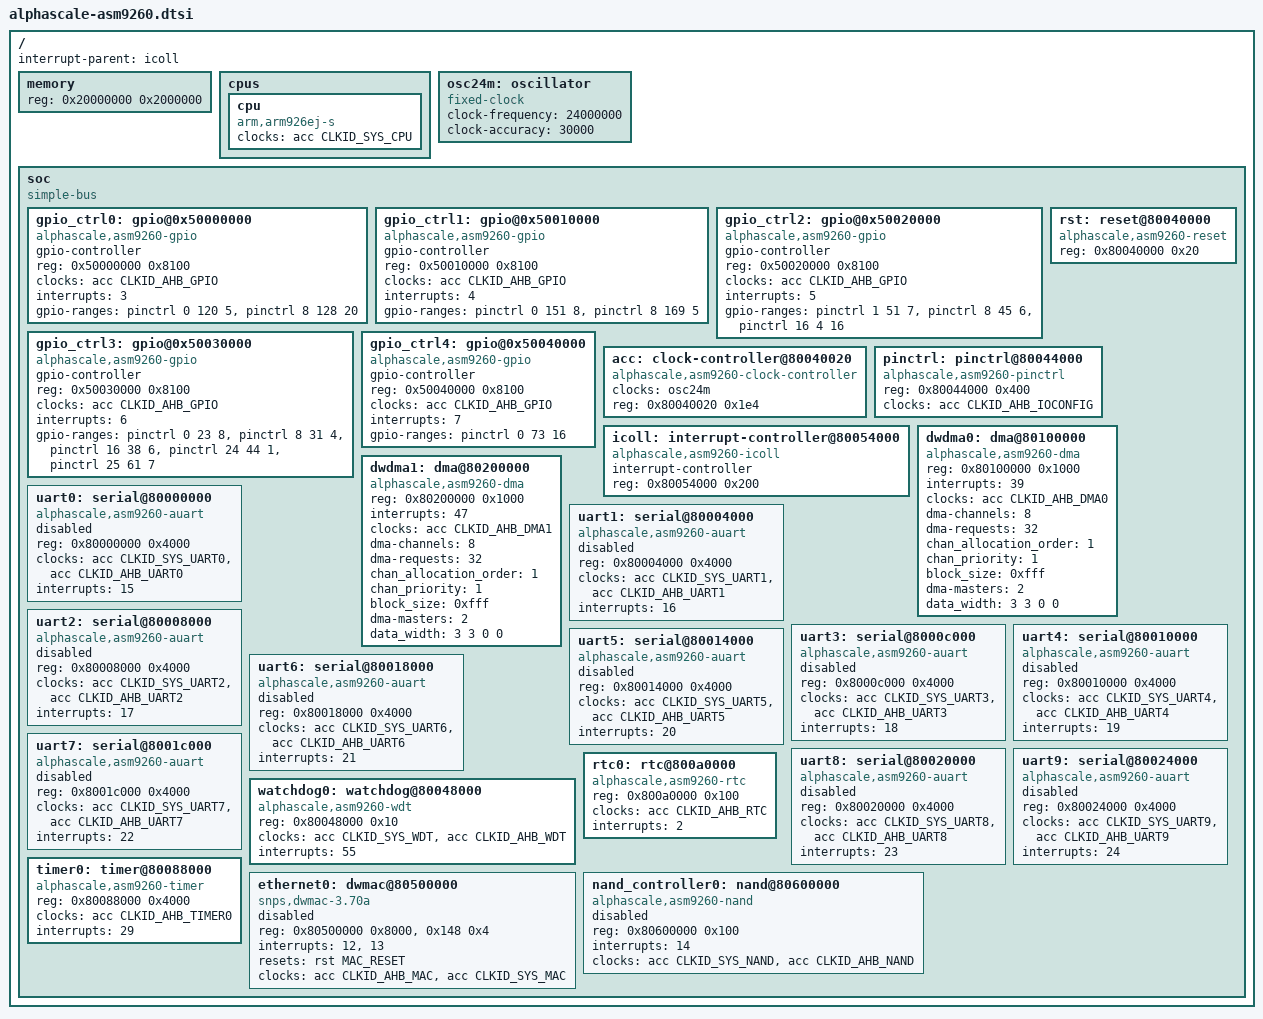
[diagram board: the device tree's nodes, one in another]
/*
 * Copyright 2014 Oleksij Rempel <linux@rempel-privat.de>
 *
 * Licensed under the X11 license or the GPL v2 (or later)
 */

#include "skeleton.dtsi"
#include <dt-bindings/clock/alphascale,asm9260.h>
#include <dt-bindings/reset/alphascale,asm9260-rst.h>

/ {
	interrupt-parent = <&icoll>;

	memory {
		device_type = "memory";
		reg = <0x20000000 0x2000000>;
	};

	cpus {
		#address-cells = <0>;
		#size-cells = <0>;

		cpu {
			compatible = "arm,arm926ej-s";
			device_type = "cpu";
			clocks = <&acc CLKID_SYS_CPU>;
		};
	};

	osc24m: oscillator {
		compatible = "fixed-clock";
		#clock-cells = <0>;
		clock-frequency = <24000000>;
		clock-accuracy = <30000>;
	};

	soc {
		#address-cells = <1>;
		#size-cells = <1>;
		compatible = "simple-bus";
		ranges;

		gpio_ctrl0: gpio@0x50000000 {
			gpio-controller;
			compatible = "alphascale,asm9260-gpio", "alphascale,asm9260-gpio-0";
			reg = <0x50000000 0x8100>;
			clocks = <&acc CLKID_AHB_GPIO>;
			clock-names = "ahb";
			interrupts = <3>;
			#gpio-cells = <2>;
			gpio-ranges = <&pinctrl 0 120 5>,
				      <&pinctrl 8 128 20>;
		};

		gpio_ctrl1: gpio@0x50010000 {
			gpio-controller;
			compatible = "alphascale,asm9260-gpio", "alphascale,asm9260-gpio-1";
			reg = <0x50010000 0x8100>;
			clocks = <&acc CLKID_AHB_GPIO>;
			clock-names = "ahb";
			interrupts = <4>;
			#gpio-cells = <2>;
			gpio-ranges = <&pinctrl 0 151 8>,
				      <&pinctrl 8 169 5>;
		};

		gpio_ctrl2: gpio@0x50020000 {
			gpio-controller;
			compatible = "alphascale,asm9260-gpio", "alphascale,asm9260-gpio-2";
			reg = <0x50020000 0x8100>;
			clocks = <&acc CLKID_AHB_GPIO>;
			clock-names = "ahb";
			interrupts = <5>;
			#gpio-cells = <2>;
			gpio-ranges = <&pinctrl 1 51 7>,
				      <&pinctrl 8 45 6>,
				      <&pinctrl 16 4 16>;
		};

		gpio_ctrl3: gpio@0x50030000 {
			gpio-controller;
			compatible = "alphascale,asm9260-gpio", "alphascale,asm9260-gpio-3";
			reg = <0x50030000 0x8100>;
			clocks = <&acc CLKID_AHB_GPIO>;
			clock-names = "ahb";
			interrupts = <6>;
			#gpio-cells = <2>;
			gpio-ranges = <&pinctrl 0 23 8>,
				      <&pinctrl 8 31 4>,
				      <&pinctrl 16 38 6>,
				      <&pinctrl 24 44 1>,
				      <&pinctrl 25 61 7>;
		};

		gpio_ctrl4: gpio@0x50040000 {
			gpio-controller;
			compatible = "alphascale,asm9260-gpio", "alphascale,asm9260-gpio-4";
			reg = <0x50040000 0x8100>;
			clocks = <&acc CLKID_AHB_GPIO>;
			clock-names = "ahb";
			interrupts = <7>;
			#gpio-cells = <2>;
			gpio-ranges = <&pinctrl 0 73 16>;
		};

		rst: reset@80040000 {
			compatible = "alphascale,asm9260-reset";
			#reset-cells = <1>;
			reg = <0x80040000 0x20>;
		};

		acc: clock-controller@80040020 {
			compatible = "alphascale,asm9260-clock-controller";
			#clock-cells = <1>;
			clocks = <&osc24m>;
			reg = <0x80040020 0x1e4>;
		};

		pinctrl: pinctrl@80044000 {
			compatible = "alphascale,asm9260-pinctrl";
			reg = <0x80044000 0x400>;
			clocks = <&acc CLKID_AHB_IOCONFIG>;
			clock-names = "ahb";
		};

		icoll: interrupt-controller@80054000 {
			compatible = "alphascale,asm9260-icoll";
			interrupt-controller;
			#interrupt-cells = <1>;
			reg = <0x80054000 0x200>;
		};

		dwdma0: dma@80100000 {
			compatible = "alphascale,asm9260-dma";
			reg = <0x80100000 0x1000>;
			interrupts = <39>;
			clocks = <&acc CLKID_AHB_DMA0>;
			/* status = "disabled"; */

			dma-channels = <8>;
			#dma-cells = <3>;
			dma-requests = <32>;
			chan_allocation_order = <1>;
			chan_priority = <1>;
			block_size = <0xfff>;
			dma-masters = <2>;
			data_width = <3 3 0 0>;
		};

		dwdma1: dma@80200000 {
			compatible = "alphascale,asm9260-dma";
			reg = <0x80200000 0x1000>;
			interrupts = <47>;
			clocks = <&acc CLKID_AHB_DMA1>;
			/* status = "disabled"; */

			dma-channels = <8>;
			#dma-cells = <3>;
			dma-requests = <32>;
			chan_allocation_order = <1>;
			chan_priority = <1>;
			block_size = <0xfff>;
			dma-masters = <2>;
			data_width = <3 3 0 0>;
		};

		uart0: serial@80000000 {
			compatible = "alphascale,asm9260-auart";
			reg = <0x80000000 0x4000>;
			clocks = <&acc CLKID_SYS_UART0>, <&acc CLKID_AHB_UART0>;
			interrupts = <15>;
			status = "disabled";
		};
		uart1: serial@80004000 {
			compatible = "alphascale,asm9260-auart";
			reg = <0x80004000 0x4000>;
			clocks = <&acc CLKID_SYS_UART1>, <&acc CLKID_AHB_UART1>;
			interrupts = <16>;
			status = "disabled";
		};
		uart2: serial@80008000 {
			compatible = "alphascale,asm9260-auart";
			reg = <0x80008000 0x4000>;
			clocks = <&acc CLKID_SYS_UART2>, <&acc CLKID_AHB_UART2>;
			interrupts = <17>;
			status = "disabled";
		};
		uart3: serial@8000c000 {
			compatible = "alphascale,asm9260-auart";
			reg = <0x8000c000 0x4000>;
			clocks = <&acc CLKID_SYS_UART3>, <&acc CLKID_AHB_UART3>;
			interrupts = <18>;
			status = "disabled";
		};
		uart4: serial@80010000 {
			compatible = "alphascale,asm9260-auart";
			reg = <0x80010000 0x4000>;
			clocks = <&acc CLKID_SYS_UART4>, <&acc CLKID_AHB_UART4>;
			interrupts = <19>;
			status = "disabled";
		};
		uart5: serial@80014000 {
			compatible = "alphascale,asm9260-auart";
			reg = <0x80014000 0x4000>;
			clocks = <&acc CLKID_SYS_UART5>, <&acc CLKID_AHB_UART5>;
			interrupts = <20>;
			status = "disabled";
		};
		uart6: serial@80018000 {
			compatible = "alphascale,asm9260-auart";
			reg = <0x80018000 0x4000>;
			clocks = <&acc CLKID_SYS_UART6>, <&acc CLKID_AHB_UART6>;
			interrupts = <21>;
			status = "disabled";
		};
		uart7: serial@8001c000 {
			compatible = "alphascale,asm9260-auart";
			reg = <0x8001c000 0x4000>;
			clocks = <&acc CLKID_SYS_UART7>, <&acc CLKID_AHB_UART7>;
			interrupts = <22>;
			status = "disabled";
		};
		uart8: serial@80020000 {
			compatible = "alphascale,asm9260-auart";
			reg = <0x80020000 0x4000>;
			clocks = <&acc CLKID_SYS_UART8>, <&acc CLKID_AHB_UART8>;
			interrupts = <23>;
			status = "disabled";
		};
		uart9: serial@80024000 {
			compatible = "alphascale,asm9260-auart";
			reg = <0x80024000 0x4000>;
			clocks = <&acc CLKID_SYS_UART9>, <&acc CLKID_AHB_UART9>;
			interrupts = <24>;
			status = "disabled";
		};

		watchdog0: watchdog@80048000 {
			compatible = "alphascale,asm9260-wdt";
			reg = <0x80048000 0x10>;
			clocks = <&acc CLKID_SYS_WDT>, <&acc CLKID_AHB_WDT>;
			clock-names = "mod", "ahb";
			interrupts = <55>;
		};

		timer0: timer@80088000 {
			compatible = "alphascale,asm9260-timer";
			reg = <0x80088000 0x4000>;
			clocks = <&acc CLKID_AHB_TIMER0>;
			interrupts = <29>;
		};

		rtc0: rtc@800a0000 {
			compatible = "alphascale,asm9260-rtc";
			reg = <0x800a0000 0x100>;
			clocks = <&acc CLKID_AHB_RTC>;
			clock-names = "ahb";
			interrupts = <2>;
		};

		ethernet0: dwmac@80500000 {
			device_type 	= "network";
			compatible	= "snps,dwmac-3.70a";
			status 		= "disabled";

			reg 		= <0x80500000 0x8000>, <0x148 0x4>;
			reg-names	= "stmmaceth", "sti-ethconf";

			/* 12, 13 or 23, 24 for mac1 ? */
			interrupts 	= <12>, <13>;
			interrupt-names = "macirq", "eth_wake_irq";
			resets			= <&rst MAC_RESET>;
			reset-names		= "stmmaceth";

/*
			snps,pbl 	= <32>;
			snps,mixed-burst;
			snps,force_sf_dma_mode;

			st,syscon	= <&syscfg_rear>;

*/
			clock-names	= "stmmaceth", "sti-ethclk";
			clocks		= <&acc CLKID_AHB_MAC>, <&acc CLKID_SYS_MAC>;
			/* clocks		= <&acc CLKID_SYS_MAC>, <&acc CLKID_AHB_MAC1>; */
		};

		nand_controller0: nand@80600000 {
			compatible = "alphascale,asm9260-nand";
			reg = <0x80600000 0x100>;
			interrupts = <14>;
			clocks = <&acc CLKID_SYS_NAND>, <&acc CLKID_AHB_NAND>;
			clock-names = "mod", "ahb";
			status = "disabled";
		};

	};
};
